NS_ :

BS_:

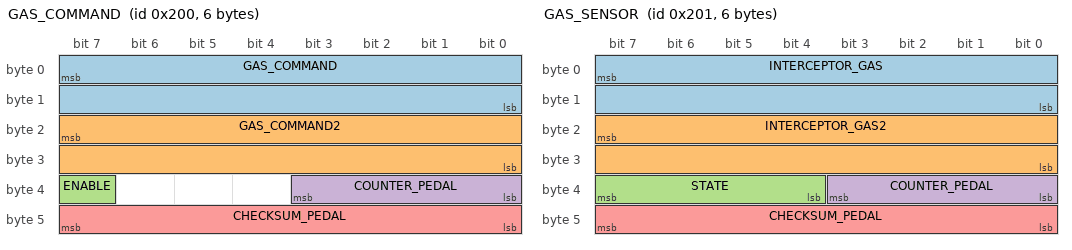
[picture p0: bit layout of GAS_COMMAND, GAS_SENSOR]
BO_ 512 GAS_COMMAND: 6 NEO
 SG_ GAS_COMMAND : 7|16@0+ (0.125677,-75.909) [0|1] "" INTERCEPTOR
 SG_ GAS_COMMAND2 : 23|16@0+ (0.251976,-76.601) [0|1] "" INTERCEPTOR
 SG_ ENABLE : 39|1@0+ (1,0) [0|1] "" INTERCEPTOR
 SG_ COUNTER_PEDAL : 35|4@0+ (1,0) [0|15] "" INTERCEPTOR
 SG_ CHECKSUM_PEDAL : 47|8@0+ (1,0) [0|255] "" INTERCEPTOR

BO_ 513 GAS_SENSOR: 6 INTERCEPTOR
 SG_ INTERCEPTOR_GAS : 7|16@0+ (0.125677,-75.909) [0|1] "" NEO
 SG_ INTERCEPTOR_GAS2 : 23|16@0+ (0.251976,-76.601) [0|1] "" NEO
 SG_ STATE : 39|4@0+ (1,0) [0|15] "" NEO
 SG_ COUNTER_PEDAL : 35|4@0+ (1,0) [0|15] "" NEO
 SG_ CHECKSUM_PEDAL : 47|8@0+ (1,0) [0|255] "" NEO

BO_ 189 EBCMRegenPaddle: 7 K17_EBCM
 SG_ RegenPaddle : 7|4@0+ (1,0) [0|0] ""  NEO

BO_ 190 ECMAcceleratorPos: 6 K20_ECM
 SG_ BrakePedalPos : 15|8@0+ (1,0) [0|0] "sticky"  NEO
 SG_ GasPedalAndAcc : 23|8@0+ (1,0) [0|0] ""  NEO

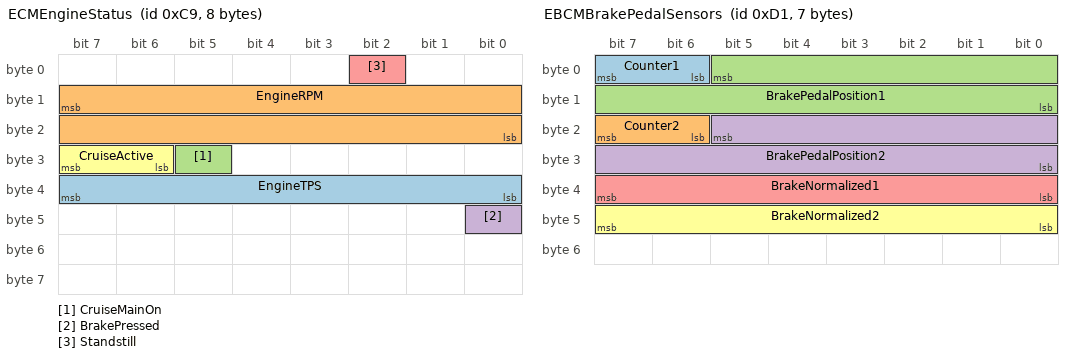
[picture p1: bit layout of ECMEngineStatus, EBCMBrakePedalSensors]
BO_ 201 ECMEngineStatus: 8 K20_ECM
 SG_ EngineTPS : 39|8@0+ (0.392156863,0) [0|100.000000065] "%" NEO
 SG_ EngineRPM : 15|16@0+ (0.25,0) [0|0] "RPM" NEO
 SG_ CruiseMainOn : 29|1@0+ (1,0) [0|1] "" NEO
 SG_ BrakePressed : 40|1@0+ (1,0) [0|1] "" NEO
 SG_ Standstill : 2|1@0+ (1,0) [0|1] "" NEO
 SG_ CruiseActive : 31|2@0+ (1,0) [0|3] "" NEO

BO_ 209 EBCMBrakePedalSensors: 7 K17_EBCM
 SG_ Counter1 : 7|2@0+ (1,0) [0|3] "" XXX
 SG_ Counter2 : 23|2@0+ (1,0) [0|3] "" XXX
 SG_ BrakePedalPosition1 : 5|14@0+ (1,0) [0|16383] "" XXX
 SG_ BrakePedalPosition2 : 21|14@0- (-1,0) [0|16383] "" XXX
 SG_ BrakeNormalized1 : 39|8@0+ (1,0) [0|255] "" XXX
 SG_ BrakeNormalized2 : 47|8@0- (-1,0) [0|255] "" XXX

BO_ 241 EBCMBrakePedalPosition: 6 K17_EBCM
 SG_ BrakePressed : 1|1@0+ (1,0) [0|1] "" XXX
 SG_ BrakePedalPosition : 15|8@0+ (1,0) [0|255] ""  NEO

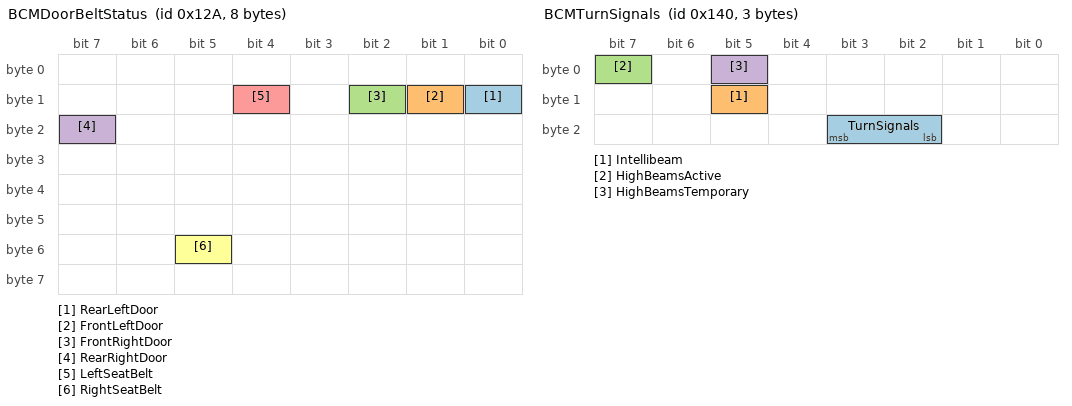
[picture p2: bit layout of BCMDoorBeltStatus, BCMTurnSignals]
BO_ 298 BCMDoorBeltStatus: 8 K9_BCM
 SG_ RearLeftDoor : 8|1@0+ (1,0) [0|0] ""  NEO
 SG_ FrontLeftDoor : 9|1@0+ (1,0) [0|0] ""  NEO
 SG_ FrontRightDoor : 10|1@0+ (1,0) [0|0] ""  NEO
 SG_ RearRightDoor : 23|1@0+ (1,0) [0|0] ""  NEO
 SG_ LeftSeatBelt : 12|1@0+ (1,0) [0|0] ""  NEO
 SG_ RightSeatBelt : 53|1@0+ (1,0) [0|0] ""  NEO

BO_ 309 ECMPRDNL: 8 K20_ECM
 SG_ PRNDL : 2|3@0+ (1,0) [0|0] ""  NEO
 SG_ ESPButton : 4|1@0+ (1,0) [0|1] "" XXX

BO_ 320 BCMTurnSignals: 3 K9_BCM
 SG_ TurnSignals : 19|2@0+ (1,0) [0|0] ""  NEO
 SG_ Intellibeam : 13|1@0+ (1,0) [0|1] "" XXX
 SG_ HighBeamsActive : 7|1@0+ (1,0) [0|1] "" XXX
 SG_ HighBeamsTemporary : 5|1@0+ (1,0) [0|1] "" XXX

BO_ 328 PSCM_148: 1 K43_PSCM

BO_ 381 ESPStatus: 6 K20_ECM
 SG_ TractionControlOn : 5|1@0+ (1,0) [0|0] ""  NEO
 SG_ MSG17D_AccPower : 35|12@0- (1,0) [0|0] ""  NEO

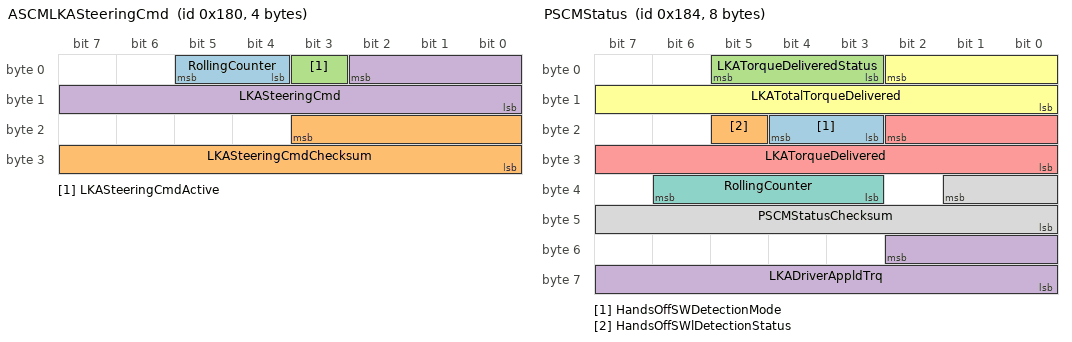
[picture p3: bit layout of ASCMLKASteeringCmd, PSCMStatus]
BO_ 384 ASCMLKASteeringCmd: 4 NEO
 SG_ RollingCounter : 5|2@0+ (1,0) [0|0] ""  NEO
 SG_ LKASteeringCmdChecksum : 19|12@0+ (1,0) [0|0] ""  NEO
 SG_ LKASteeringCmdActive : 3|1@0+ (1,0) [0|0] ""  NEO
 SG_ LKASteeringCmd : 2|11@0- (1,0) [0|0] ""  NEO

BO_ 388 PSCMStatus: 8 K43_PSCM
 SG_ HandsOffSWDetectionMode : 20|2@0+ (1,0) [0|3] "" NEO
 SG_ HandsOffSWlDetectionStatus : 21|1@0+ (1,0) [0|1] "" NEO
 SG_ LKATorqueDeliveredStatus : 5|3@0+ (1,0) [0|7] "" NEO
 SG_ LKADriverAppldTrq : 50|11@0- (0.01,0) [-10.24|10.23] "Nm" NEO
 SG_ LKATorqueDelivered : 18|11@0- (0.01,0) [0|1] "" NEO
 SG_ LKATotalTorqueDelivered : 2|11@0- (0.01,0) [-10.24|10.23] "Nm" NEO
 SG_ RollingCounter : 38|4@0+ (1,0) [0|15] "" XXX
 SG_ PSCMStatusChecksum : 33|10@0+ (1,0) [0|1023] "" XXX

BO_ 417 AcceleratorPedal: 7 XXX
 SG_ AcceleratorPedal : 55|8@0+ (1,0) [0|0] ""  NEO

BO_ 451 GasAndAcc: 8 XXX
 SG_ GasPedalAndAcc2 : 55|8@0+ (1,0) [0|0] ""  NEO

BO_ 452 AcceleratorPedal2: 8 XXX
 SG_ CruiseState : 15|3@0+ (1,0) [0|7] ""  NEO
 SG_ AcceleratorPedal2 : 47|8@0+ (1,0) [0|0] ""  NEO

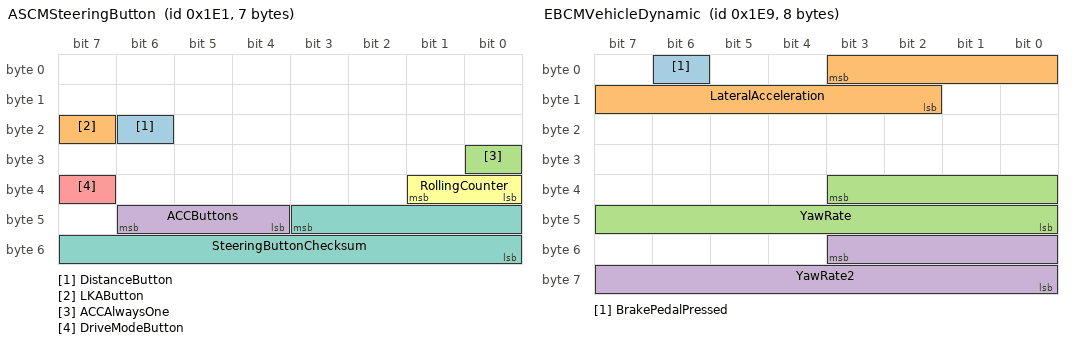
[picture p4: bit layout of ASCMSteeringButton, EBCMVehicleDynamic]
BO_ 481 ASCMSteeringButton: 7 K124_ASCM
 SG_ DistanceButton : 22|1@0+ (1,0) [0|0] ""  NEO
 SG_ LKAButton : 23|1@0+ (1,0) [0|0] ""  NEO
 SG_ ACCAlwaysOne : 24|1@0+ (1,0) [0|1] "" XXX
 SG_ ACCButtons : 46|3@0+ (1,0) [0|0] ""  NEO
 SG_ DriveModeButton : 39|1@0+ (1,0) [0|1] "" XXX
 SG_ RollingCounter : 33|2@0+ (1,0) [0|3] "" NEO
 SG_ SteeringButtonChecksum : 43|12@0+ (1,0) [0|255] "" NEO

BO_ 485 PSCMSteeringAngle: 8 K43_PSCM
 SG_ SteeringWheelAngle : 15|16@0- (0.0625,0) [-2047|2047] "deg"  NEO
 SG_ SteeringWheelRate : 27|12@0- (1,0) [-2047|2047] "deg/s"  NEO

BO_ 489 EBCMVehicleDynamic: 8 K17_EBCM
 SG_ BrakePedalPressed : 6|1@0+ (1,0) [0|0] "" NEO
 SG_ LateralAcceleration : 3|10@0- (0.161,0) [-2047|2047] "m/s2" NEO
 SG_ YawRate : 35|12@0- (0.625,0) [0|1] "" NEO
 SG_ YawRate2 : 51|12@0- (0.0625,0) [-2047|2047] "grad/s" NEO

BO_ 352 BCMImmobilizer: 5 K9_BCM
 SG_ ImmobilizerInfo : 7|32@0+ (1,0) [0|4294967295] "" XXX

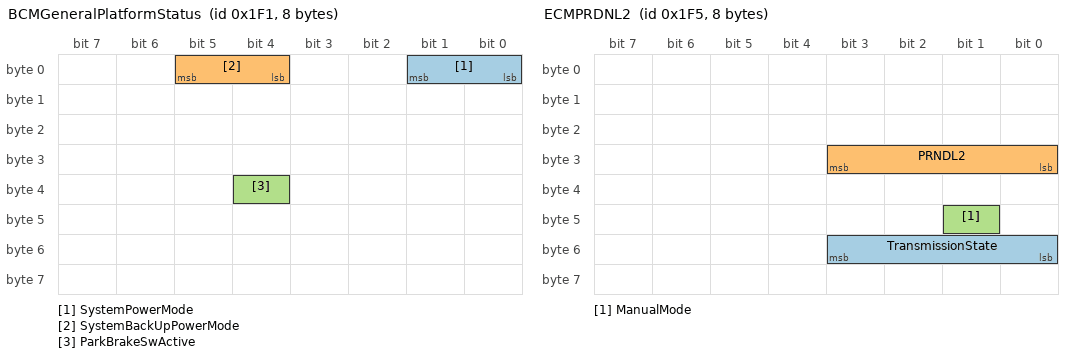
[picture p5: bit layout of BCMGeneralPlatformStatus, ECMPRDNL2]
BO_ 497 BCMGeneralPlatformStatus: 8 K9_BCM
 SG_ SystemPowerMode : 1|2@0+ (1,0) [0|3] "" XXX
 SG_ SystemBackUpPowerMode : 5|2@0+ (1,0) [0|3] "" XXX
 SG_ ParkBrakeSwActive : 36|1@0+ (1,0) [0|3] "" XXX

BO_ 501 ECMPRDNL2: 8 K20_ECM
 SG_ TransmissionState : 48|4@1+ (1,0) [0|7] "" NEO
 SG_ PRNDL2 : 27|4@0+ (1,0) [0|255] "" NEO
 SG_ ManualMode : 41|1@0+ (1,0) [0|1] "" NEO

BO_ 532 BRAKE_RELATED: 6 XXX
 SG_ UserBrakePressure : 0|9@0+ (1,0) [0|511] "" XXX

BO_ 560 EPBStatus: 8 EPB
 SG_ EPBClosed : 12|1@0+ (1,0) [0|1] ""  NEO

BO_ 562 EBCMFrictionBrakeStatus: 8 K17_EBCM
 SG_ FrictionBrakeUnavailable : 46|1@0+ (1,0) [0|1] "" XXX

BO_ 608 SPEED_RELATED: 8 XXX
 SG_ RollingCounter : 5|2@0+ (1,0) [0|0] "" XXX
 SG_ ClusterSpeed : 31|8@0+ (1,0) [0|0] "" XXX

BO_ 711 BECMBatteryVoltageCurrent: 6 K17_EBCM
 SG_ HVBatteryVoltage : 31|12@0+ (0.125,0) [0|511.875] "V"  NEO
 SG_ HVBatteryCurrent : 12|13@0- (0.15,0) [-614.4|614.25] "A"  NEO

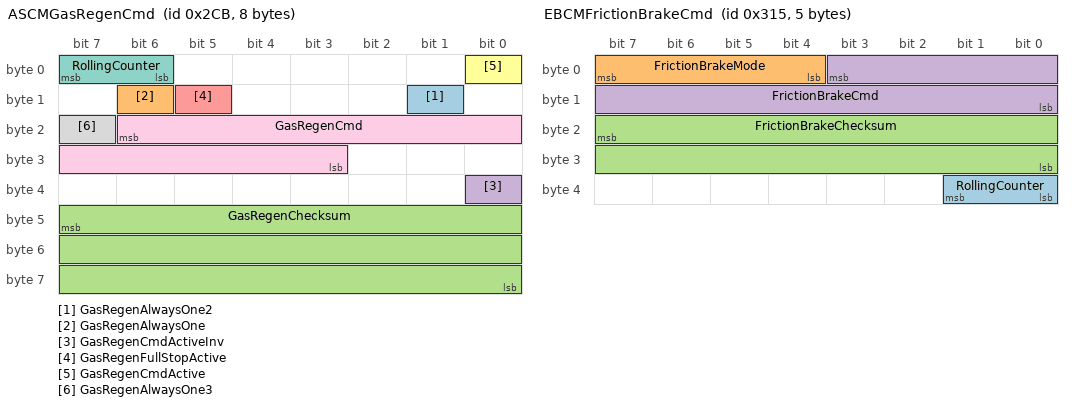
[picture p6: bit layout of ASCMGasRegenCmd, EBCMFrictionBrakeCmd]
BO_ 715 ASCMGasRegenCmd: 8 K124_ASCM
 SG_ GasRegenAlwaysOne2 : 9|1@0+ (1,0) [0|1] ""  NEO
 SG_ GasRegenAlwaysOne : 14|1@0+ (1,0) [0|1] ""  NEO
 SG_ GasRegenChecksum : 47|24@0+ (1,0) [0|0] ""  NEO
 SG_ GasRegenCmdActiveInv : 32|1@0+ (1,0) [0|0] ""  NEO
 SG_ GasRegenFullStopActive : 13|1@0+ (1,0) [0|0] ""  NEO
 SG_ GasRegenCmdActive : 0|1@0+ (1,0) [0|0] ""  NEO
 SG_ RollingCounter : 7|2@0+ (1,0) [0|0] ""  NEO
 SG_ GasRegenAlwaysOne3 : 23|1@0+ (1,0) [0|1] ""  NEO
 SG_ GasRegenCmd : 22|12@0+ (1,0) [0|0] ""  NEO

BO_ 717 ASCM_2CD: 5 K124_ASCM

BO_ 761 BRAKE_RELATED_2: 7 XXX
 SG_ UserBrakePressure2 : 47|9@0+ (1,0) [0|511] "" XXX

BO_ 789 EBCMFrictionBrakeCmd: 5 K124_ASCM
 SG_ RollingCounter : 33|2@0+ (1,0) [0|0] ""  NEO
 SG_ FrictionBrakeMode : 7|4@0+ (1,0) [0|0] ""  NEO
 SG_ FrictionBrakeChecksum : 23|16@0+ (1,0) [0|0] ""  NEO
 SG_ FrictionBrakeCmd : 3|12@0- (1,0) [0|0] ""  NEO

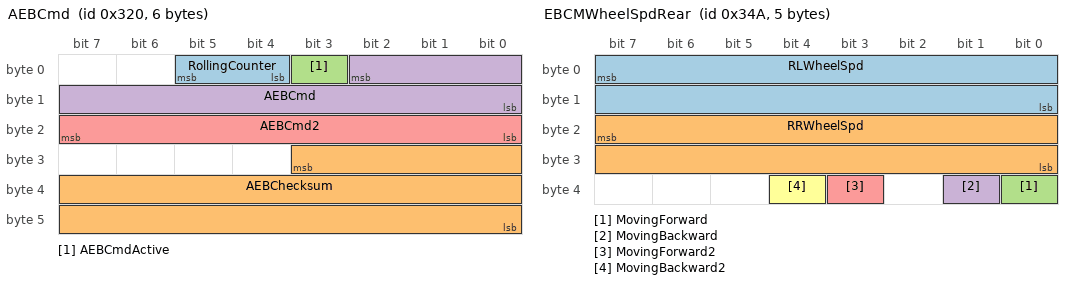
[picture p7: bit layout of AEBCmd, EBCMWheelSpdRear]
BO_ 800 AEBCmd: 6 K124_ASCM
 SG_ RollingCounter : 5|2@0+ (1,0) [0|3] "" NEO
 SG_ AEBChecksum : 27|20@0+ (1,0) [0|0] "" NEO
 SG_ AEBCmdActive : 3|1@1+ (1,0) [0|1] "" NEO
 SG_ AEBCmd : 2|11@0+ (1,0) [0|0] "" NEO
 SG_ AEBCmd2 : 23|8@0+ (1,0) [0|0] "" NEO

BO_ 810 TCICOnStarGPSPosition: 8 K73_TCIC
 SG_ GPSLongitude : 39|32@0+ (1,-2147483648) [0|0] "milliarcsecond"  NEO
 SG_ GPSLatitude : 7|32@0+ (1,0) [0|0] "milliarcsecond"  NEO

BO_ 840 EBCMWheelSpdFront: 5 K17_EBCM
 SG_ FLWheelSpd : 7|16@0+ (0.0311,0) [0|255] "km/h"  NEO
 SG_ FRWheelSpd : 23|16@0+ (0.0311,0) [0|255] "km/h"  NEO

BO_ 842 EBCMWheelSpdRear: 5 K17_EBCM
 SG_ RLWheelSpd : 7|16@0+ (0.0311,0) [0|255] "km/h"  NEO
 SG_ RRWheelSpd : 23|16@0+ (0.0311,0) [0|255] "km/h"  NEO
 SG_ MovingForward : 32|1@0+ (1,0) [0|1] "" XXX
 SG_ MovingBackward : 33|1@0+ (1,0) [0|1] "" XXX
 SG_ MovingForward2 : 35|1@1+ (1,0) [0|1] "" XXX
 SG_ MovingBackward2 : 36|1@0+ (1,0) [0|1] "" XXX

BO_ 869 ASCM_365: 4 K124_ASCM

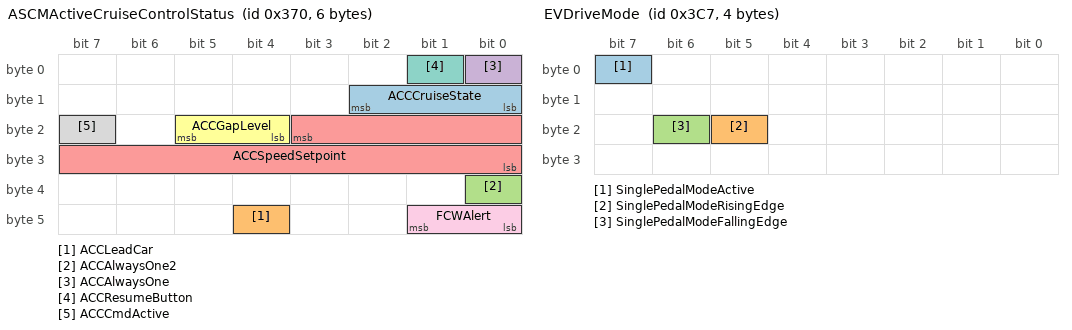
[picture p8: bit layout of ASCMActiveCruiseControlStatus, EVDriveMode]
BO_ 880 ASCMActiveCruiseControlStatus: 6 K124_ASCM
 SG_ ACCCruiseState : 8|3@1+ (1,0) [0|7] "" XXX
 SG_ ACCLeadCar : 44|1@0+ (1,0) [0|0] "" Vector__XXX
 SG_ ACCAlwaysOne2 : 32|1@0+ (1,0) [0|0] "" Vector__XXX
 SG_ ACCAlwaysOne : 0|1@0+ (1,0) [0|0] "" Vector__XXX
 SG_ ACCSpeedSetpoint : 19|12@0+ (0.0625,0) [0|255.9375] "km/h"  NEO
 SG_ ACCGapLevel : 21|2@0+ (1,0) [0|0] ""  NEO
 SG_ ACCResumeButton : 1|1@0+ (1,0) [0|0] ""  NEO
 SG_ ACCCmdActive : 23|1@0+ (1,0) [0|0] ""  NEO
 SG_ FCWAlert : 41|2@0+ (1,0) [0|3] "" XXX

BO_ 967 EVDriveMode: 4 XXX
 SG_ SinglePedalModeActive : 7|1@0+ (1,0) [0|1] "" XXX
 SG_ SinglePedalModeRisingEdge : 21|1@0+ (1,0) [0|1] "" XXX
 SG_ SinglePedalModeFallingEdge : 22|1@0+ (1,0) [0|1] "" XXX

BO_ 977 ECMCruiseControl: 8 K20_ECM
 SG_ CruiseActive : 39|1@0+ (1,0) [0|3] "" NEO
 SG_ CruiseSetSpeed : 19|12@0+ (0.0625,0) [0|0] "km/h" NEO

BO_ 1001 ECMVehicleSpeed: 8 K20_ECM
 SG_ VehicleSpeed : 7|16@0+ (0.01,0) [0|0] "mph"  NEO
 SG_ VehicleSpeedLeft : 39|16@0+ (0.01,0) [0|0] "mph" NEO

BO_ 1033 ASCMKeepAlive: 7 NEO
 SG_ ASCMKeepAliveAllZero : 7|56@0+ (1,0) [0|0] ""  NEO

BO_ 1034 ASCM_40A: 7 K124_ASCM

BO_ 1217 ECMEngineCoolantTemp: 8 K20_ECM
 SG_ EngineCoolantTemp : 23|8@0+ (1,-40) [0|0] "C"  NEO

BO_ 1249 VIN_Part2: 8 K20_ECM
 SG_ VINPart2 : 7|64@0+ (1,0) [0|0] ""  NEO

BO_ 1296 ASCM_510: 4 K124_ASCM

BO_ 1300 VIN_Part1: 8 K20_ECM
 SG_ VINPart1 : 7|64@0+ (1,0) [0|0] ""  NEO

BO_ 1912 PSCM_778: 8 K43_PSCM

BO_ 1930 ASCM_78A: 7 K124_ASCM

BO_TX_BU_ 384 : K124_ASCM,NEO;
BO_TX_BU_ 880 : NEO,K124_ASCM;
BO_TX_BU_ 1033 : K124_ASCM,NEO;
BO_TX_BU_ 715 : NEO,K124_ASCM;
BO_TX_BU_ 789 : NEO,K124_ASCM;
BO_TX_BU_ 800 : NEO,K124_ASCM;

BU_: IAP ODS _4WD BCM HUD DATC MDPS AAF_Tester AEMC SMK _4WD EPB CUBIS MTS TMU EVP CGW TPMS LPI DI_BOX SPAS EMS LCA TCU IBOX FATC AFLS FPCM SCC AHLS AVM ABS SNV OPI PGS SAS AAF Dummy LDWS_LKAS LVR ESC PSB CLU ECS ACU REA

CM_ "AUTOGENERATED FILE, DO NOT EDIT";

CM_ "Imported file _comma.dbc starts here";
CM_ "BO_ STEERING_IPAS_COMMA: Copy of msg 614 so we can do angle control while the Park Assist ECU is connected (Panda spoofs 614 with 359 on connector J70). Note that addresses 0x266 and 0x167 are checksum-invariant";

CM_ "BO_ SECONDARY_STEER_ANGLE: ZSS is a high-precision steering angle sensor that can replace the lower resolution sensor in most TSS1 Toyotas. Learn more: https://github.com/commaai/openpilot/wiki/Toyota-Lexus#zorro-steering-sensor-zss";

CM_ "BO_ SDSU: The sDSU is a modified DSU for use in TSS1 Toyotas. Learn more: https://github.com/wocsor/panda/tree/smart_dsu";
CM_ SG_ 767 FD_BUTTON "The follow distance button signal as forwarded by the sdsu";

CM_ "Imported file _toyota_2017.dbc starts here";
CM_ SG_ 36 YAW_RATE "verify";
CM_ SG_ 36 ACCEL_X "x-axis accel";
CM_ SG_ 37 STEER_FRACTION "1/15th of the signal STEER_ANGLE, which is 1.5 deg; note that 0x8 is never set";
CM_ SG_ 37 STEER_RATE "factor is tbd";
CM_ SG_ 466 NEUTRAL_FORCE "force in newtons the engine/electric motors are applying without any acceleration commands or user input";
CM_ SG_ 466 ACC_BRAKING "whether brakes are being actuated from ACC command";
CM_ SG_ 466 ACCEL_NET "net acceleration produced by the system, given ACCEL_CMD, road grade and other factors";
CM_ SG_ 466 CRUISE_STATE "Active state is 8, if standstill is requested will switch to state 11(3 sec timer), after timer is elapsed will switch into state 7(standstill). If plus button was pressed - status 9, minus button pressed - status 10";
CM_ SG_ 467 ACC_FAULTED "1 when ACC is faulted and the PCM disallows engagement";
CM_ SG_ 467 SET_SPEED "43 km/h are shown as 28 mph, so conversion isn't perfect";
CM_ SG_ 467 LOW_SPEED_LOCKOUT "in low speed lockout, system would always disengage below 28mph";
CM_ SG_ 560 BRAKE_PRESSED "another brake pressed?";
CM_ SG_ 581 GAS_PEDAL "it seems slightly filtered";
CM_ SG_ 608 STEER_TORQUE_DRIVER "driver torque";
CM_ SG_ 608 STEER_OVERRIDE "set when driver torque exceeds a certain value";
CM_ SG_ 614 ANGLE "set to measured angle when ipas control isn't active";
CM_ SG_ 643 _COUNTER "only used on cars that use this msg for cruise control";
CM_ SG_ 643 BRAKE_STATUS "only used on cars that use this msg for cruise control";
CM_ SG_ 643 PRECOLLISION_ACTIVE "set 0.5s before any braking";
CM_ SG_ 835 ACC_TYPE "if 2, car is likely to have a permanent low speed lockout. 1 is ok";
CM_ SG_ 835 RADAR_DIRTY "Display Clean Radar Sensor message on HUD";
CM_ SG_ 835 ACC_MALFUNCTION "display ACC fault on dash if set to 1";
CM_ SG_ 835 ACC_CUT_IN "Display blinking yellow lead if set to 1";
CM_ SG_ 835 DISTANCE "Cycle through ACC following distance from long, mid, short when set to 1";
CM_ SG_ 835 ITS_CONNECT_LEAD "Displayed when lead car is capable of ITS Connect";
CM_ SG_ 835 ALLOW_LONG_PRESS "Enable Toyota's factory set speed increment behaviour, available on both metrics cars and imperial unit cars";
CM_ SG_ 835 PERMIT_BRAKING "Original ACC has this going high when a car in front is detected. In openpilot and before the PERMIT_BRAKING name, this was 'SET_ME_1' and is hardcoded to be high. Unsure if only informational or has an effect though existing usage in openpilot is to always set it to 1. Originally 'PMTBRKG' in the leaked toyota_2017_ref_pt.dbc file and name expansion speculated to be PerMiT BRaKinG.";
CM_ SG_ 835 ACCEL_CMD_ALT "Copy of main ACCEL_CMD, but across 8 bits instead of 16 bits like ACCEL_CMD. Unsure if only informational or has an effect. Likely informational as existing openpilot sets this to 0 and no loss of functionality observed. Originally 'AT_RAW' in leaked toyota_2017_ref_pt.dbc file.";
CM_ SG_ 865 GAS_PEDAL_ALT "copy of main GAS_PEDAL. Both use 8 bits. Might indicate that this message is for pedals.";
CM_ SG_ 865 CLUTCH_RELEASED "boolean of clutch for 6MT.";
CM_ SG_ 865 ACC_FAULTED "1 when ACC is faulted and the PCM disallows engagement. Also describes a lockout when the ACC_CONTROL->ACC_MALFUNCTION bit is set.";
CM_ SG_ 921 UI_SET_SPEED "set speed shown in the vehicle's UI with the vehicle's unit";
CM_ SG_ 921 TEMP_ACC_FAULTED "1 when the UI is displaying or playing fault-related alerts or sounds. Also 1 when pressing main on.";
CM_ SG_ 951 BRAKE_LIGHTS_ACC "brake lights when ACC commands decel";
CM_ SG_ 956 GEAR "on 6MT, only R shows.";
CM_ SG_ 1009 UI_SET_SPEED "units seem to be whatever the car is set to";
CM_ SG_ 1041 PCS_INDICATOR "Pre-Collision System Indicator";
CM_ SG_ 1041 PCS_SENSITIVITY "Pre-Collision System Sensitivity";
CM_ SG_ 1041 PCS_DUST "alert: Front Camera Low Visibility Unavailable See Owner's Manual";
CM_ SG_ 1041 PCS_DUST2 "alert: Pre-Collision System Radar Sensor Blocked Unavailable Clean Radar Sensor";
CM_ SG_ 1041 PCS_TEMP "alert: Front Camera Out of Temperature Range Unavailable Wait until Normal Temperature";
CM_ SG_ 1041 PCS_TEMP2 "alert: Pre-Collision System Out of Temperature Range Unavailable See Owner's Manual";
CM_ SG_ 1041 FRD_ADJ "alert: ERROR ADJUSTING FRONT RADAR BEAM";
CM_ SG_ 1042 LDA_SA_TOGGLE "LDA Steering Assist Toggle";
CM_ SG_ 1042 LDW_EXIST "Unclear what this is, it's usually set to 0";
CM_ SG_ 1042 LDA_SENSITIVITY "LDA Sensitivity";
CM_ SG_ 1042 LDA_ON_MESSAGE "Display LDA Turned ON message";
CM_ SG_ 1042 REPEATED_BEEPS "LDA audible warning";
CM_ SG_ 1042 LDA_UNAVAILABLE_QUIET "LDA toggles and sensitivity settings are greyed out if set to 1";
CM_ SG_ 1042 LDA_MESSAGES "Various LDA Messages";
CM_ SG_ 1042 LDA_FRONT_CAMERA_BLOCKED "originally LDAFCVB, LDA related settings are greyed out if set to 1";
CM_ SG_ 1042 TAKE_CONTROL "Please Control Steering Wheel warning";
CM_ SG_ 1042 LANE_SWAY_TOGGLE "Lane Sway Warning System SWS Switch";
CM_ SG_ 1042 LANE_SWAY_WARNING "Lane Sway Warning System Triggered";
CM_ SG_ 1042 LANE_SWAY_FLD "Unknown signal for Lane Sway Warning System, set to 7 on stock system when SWS is enabled, 0 when SWS is disabled";
CM_ SG_ 1042 LANE_SWAY_BUZZER "Similar to TWO_BEEPS";
CM_ SG_ 1042 SET_ME_X01 "empty bit on leaked dbc, always set to 1 during normal operations";
CM_ SG_ 1042 SET_ME_X02 "empty bit on leaked dbc, always set to 2 during normal operations";
CM_ SG_ 1083 STATE "when the dashboard button is pressed, the value changes from zero to non-zero";
CM_ SG_ 1161 SPDVAL1 "Numbers 0-199 is displayed, 200-254 displays circle without number and 255 is for no limit.";
CM_ SG_ 1161 SYNCID1 "counter from 1 to f at 1 Hz";
CM_ SG_ 1161 SPDVAL2 "conditional speed value 70";
CM_ SG_ 1162 SGNNUMP "1 if SPDVAL1 is set, otherwise 0";
CM_ SG_ 1162 SYNCID2 "counter from 1 to f at 1 Hz";
CM_ SG_ 1163 TSREQPD "always 1";
CM_ SG_ 1163 TSRMSW "always 1";
CM_ SG_ 1163 OTSGNNTM "always 3";
CM_ SG_ 1163 NTLVLSPD "always 3";
CM_ SG_ 1163 OVSPNTM "always 3";
CM_ SG_ 1163 OVSPVALL "-5 at start then 2 after 2 seconds";
CM_ SG_ 1163 OVSPVALM "-5 at start then 5 after 2 seconds";
CM_ SG_ 1163 OVSPVALH "-5 at start then 10 after 2 seconds";
CM_ SG_ 1163 TSRSPU "always 1";
CM_ SG_ 1552 UI_SPEED "Does not appear to match dash";
CM_ SG_ 1552 METER_SLIDER_BRIGHTNESS_PCT "Combination display brightness setting, scales from 12 per cent to 100 per cent, reflects combination meter settings only, not linked with headlight state";
CM_ SG_ 1552 METER_SLIDER_LOW_BRIGHTNESS "Combination display low brightness mode, also controls footwell lighting";
CM_ SG_ 1552 METER_SLIDER_DIMMED "Combination display slider not at max, reflects combination meter settings only, not linked with headlight state";
CM_ SG_ 1553 ODOMETER "Unit is dependent upon units signal";
CM_ SG_ 1592 LOCK_STATUS_CHANGED "1 on rising edge of lock/unlocking";
CM_ SG_ 1592 LOCK_STATUS "The next 3 bits always seem to follow this signal.";
CM_ SG_ 1592 LOCKED_VIA_KEYFOB "1 for as long as car is locked with key fob or door handle touch";

CM_ "toyota_nodsu_pt.dbc starts here";

CM_ SG_ 401 PERCENTAGE "driver override percentage (0-100), very close to steeringPressed in OP";
CM_ SG_ 401 TORQUE_WIND_DOWN "used to wind down torque on user override";
CM_ SG_ 401 ANGLE "angle of car relative to lane center on LTA camera";
CM_ SG_ 401 STEER_ANGLE_CMD "desired angle, OEM steers up to 95 degrees, no angle limit but torque will bottom out";
CM_ SG_ 401 CLEAR_HOLD_STEERING_ALERT "set to 1 when user clears LKAS_HUD->LDA_ALERT ('Hold Steering') by applying torque to steering wheel";
CM_ SG_ 401 STEER_REQUEST "enable bit for steering, 1 to steer, 0 to not";
CM_ SG_ 401 STEER_REQUEST_2 "enable bit for steering, 1 to steer, 0 to not";
CM_ SG_ 401 LKA_ACTIVE "1 when using LTA for LKA";
CM_ SG_ 401 SETME_X1 "usually 1, seen at 0 on some South American Corollas indicating lack of stock Lane Tracing Assist";
CM_ SG_ 401 SETME_X3 "almost completely correlates with Toyota Safety Sense version, but may instead describe max torque when using LTA. if TSS 2.5 or 2022 RAV4, this is always 1. if TSS 2.0 this is always 3 (or 0 on Alphard, Highlander, NX)";
CM_ SG_ 550 BRAKE_PRESSURE "seems prop to pedal force";
CM_ SG_ 550 BRAKE_POSITION "seems proportional to pedal displacement, unclear the max value of 0x1c8";
CM_ SG_ 610 TYPE "seems 1 on Corolla, 0 on all others";
CM_ SG_ 881 GAS_PEDAL "not set on all cars, only seen on TSS 2.5 Camry Hybrid so far";
CM_ SG_ 881 STEER_ANGLE "matches STEER_TORQUE_SENSOR->STEER_ANGLE";
CM_ SG_ 881 TURN_SIGNALS "flipped on some cars";
CM_ SG_ 881 LDA_SA_TOGGLE "not applicable for all cars";
CM_ SG_ 881 LTA_STEER_REQUEST "only applicable for TSS 2.5: matches STEERING_LTA->STEER_REQUEST";
CM_ SG_ 881 UNKNOWN "related to steering wheel angle";
CM_ SG_ 881 STEERING_PRESSED "only applicable for TSS 2.5: low sensitivity steering wheel pressed by driver signal";
CM_ SG_ 1014 L_ADJACENT "vehicle adjacent left side of car. enabled above 10mph, regardless of ADJACENT_ENABLED or APPROACHING_ENABLED";
CM_ SG_ 1014 L_APPROACHING "vehicle approaching from left side of car. enabled above 10mph, regardless of ADJACENT_ENABLED or APPROACHING_ENABLED";
CM_ SG_ 1014 R_ADJACENT "vehicle adjacent right side of car. enabled above 10mph, regardless of ADJACENT_ENABLED or APPROACHING_ENABLED";
CM_ SG_ 1014 R_APPROACHING "vehicle approaching from right side of car. enabled above 10mph, regardless of ADJACENT_ENABLED or APPROACHING_ENABLED";
CM_ SG_ 1014 ADJACENT_ENABLED "when BSM is enabled in settings, this is on along with APPROACHING_ENABLED. this controls bsm alert visibility";
CM_ SG_ 1014 APPROACHING_ENABLED "when BSM is enabled in settings, this is on along with ADJACENT_ENABLED. this controls bsm alert visibility";
